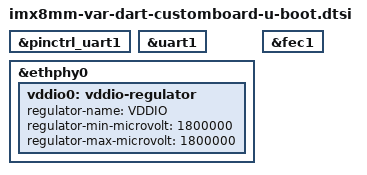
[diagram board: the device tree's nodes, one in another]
#include "imx8mm-var-common-u-boot.dtsi"

&pinctrl_uart1 {
	u-boot,dm-spl;
};

&uart1 {
	u-boot,dm-spl;
};

&ethphy0 {
       vddio0: vddio-regulator {
               regulator-name = "VDDIO";
               regulator-min-microvolt = <1800000>;
               regulator-max-microvolt = <1800000>;
       };
};

&fec1 {
	/* SPL now owns the PHY reset sequence before full U-Boot starts. */
	/delete-property/ phy-reset-gpios;
	/delete-property/ phy-reset-duration;
	/delete-property/ phy-reset-post-delay;
};
